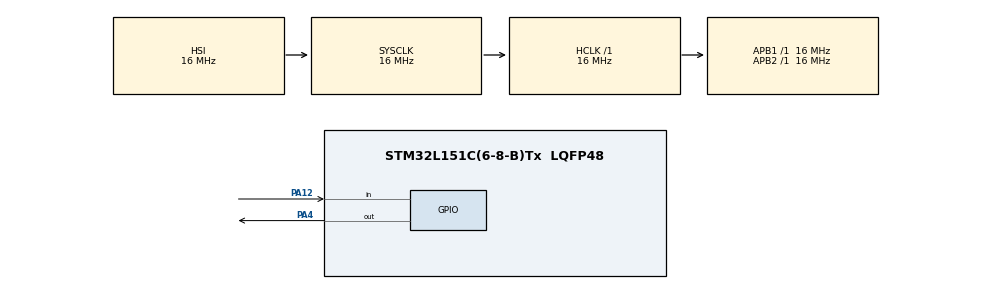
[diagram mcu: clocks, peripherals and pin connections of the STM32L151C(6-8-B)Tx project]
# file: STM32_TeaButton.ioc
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Mcu.Family=STM32L1
RCC.MSI_VALUE=2097000
RCC.SYSCLKSource=RCC_SYSCLKSOURCE_HSI
ProjectManager.StackSize=0x400
PA13.Signal=SYS_JTMS-SWDIO
PA12.Signal=GPIO_Input
ProjectManager.TargetToolchain=STM32CubeIDE
RCC.HCLKFreq_Value=16000000
RCC.APB2TimFreq_Value=16000000
RCC.LSE_VALUE=32768
RCC.AHBFreq_Value=16000000
RCC.HSE_VALUE=8000000
PB3.Mode=Trace_Asynchronous_SW
board=custom
RCC.VCOOutputFreq_Value=192000000
RCC.PLLMUL=RCC_PLL_MUL12
RCC.APB2Freq_Value=16000000
PA14.Mode=Trace_Asynchronous_SW
PA13.Mode=Trace_Asynchronous_SW
Mcu.Name=STM32L151C(6-8-B)Tx
RCC.48MHZClocksFreq_Value=96000000
PB3.Signal=SYS_JTDO-TRACESWO
PA4.Signal=GPIO_Output
RCC.SYSCLKFreq_VALUE=16000000
Mcu.Package=LQFP48
PA14.Signal=SYS_JTCK-SWCLK
ProjectManager.HeapSize=0x200
RCC.HSI_VALUE=16000000
NVIC.PriorityGroup=NVIC_PRIORITYGROUP_4
RCC.APB1TimFreq_Value=16000000
RCC.APB1Freq_Value=16000000

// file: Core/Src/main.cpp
/* USER CODE BEGIN Header */
/**
  ******************************************************************************
  * @file           : main.c
  * @brief          : Main program body
  ******************************************************************************
  * @attention
  *
  * <h2><center>&copy; Copyright (c) 2021 STMicroelectronics.
  * All rights reserved.</center></h2>
  *
  * This software component is licensed by ST under BSD 3-Clause license,
  * the "License"; You may not use this file except in compliance with the
  * License. You may obtain a copy of the License at:
  *                        opensource.org/licenses/BSD-3-Clause
  *
  ******************************************************************************
  */
/* USER CODE END Header */
#include "main.h"

/* USER CODE BEGIN Includes */
#include <stdio.h>
#include <TeaButton.h>
/* USER CODE END Includes */

void SystemClock_Config(void);
static void MX_GPIO_Init(void);

int main(void)
{

  /* MCU Configuration--------------------------------------------------------*/

  /* Reset of all peripherals, Initializes the Flash interface and the Systick. */
   HAL_Init();

  /* Configure the system clock */
  SystemClock_Config();

  /* Initialize all configured peripherals */
  MX_GPIO_Init();
  /* USER CODE BEGIN 2 */
  //HAL_GPIO_ReadPin(GPIOx, GPIO_Pin);

  TeaButton bt1 = TeaButton(GPIOA, GPIO_PIN_12);
  /* USER CODE END 2 */

  /* Infinite loop */
  while (1)
  {

    /* USER CODE BEGIN 3 */
	  if (bt1.isPress()){
		  HAL_GPIO_TogglePin(GPIOA, GPIO_PIN_4);
	  }
	  if (bt1.isRelease()){
		  HAL_GPIO_TogglePin(GPIOA, GPIO_PIN_4);
	  }
  }
  /* USER CODE END 3 */
}

void SystemClock_Config(void)
{
  RCC_OscInitTypeDef RCC_OscInitStruct = {0};
  RCC_ClkInitTypeDef RCC_ClkInitStruct = {0};

  /** Configure the main internal regulator output voltage
  */
  __HAL_PWR_VOLTAGESCALING_CONFIG(PWR_REGULATOR_VOLTAGE_SCALE1);
  /** Initializes the RCC Oscillators according to the specified parameters
  * in the RCC_OscInitTypeDef structure.
  */
  RCC_OscInitStruct.OscillatorType = RCC_OSCILLATORTYPE_HSI;
  RCC_OscInitStruct.HSIState = RCC_HSI_ON;
  RCC_OscInitStruct.HSICalibrationValue = RCC_HSICALIBRATION_DEFAULT;
  RCC_OscInitStruct.PLL.PLLState = RCC_PLL_NONE;
  if (HAL_RCC_OscConfig(&RCC_OscInitStruct) != HAL_OK)
  {
    Error_Handler();
  }
  /** Initializes the CPU, AHB and APB buses clocks
  */
  RCC_ClkInitStruct.ClockType = RCC_CLOCKTYPE_HCLK|RCC_CLOCKTYPE_SYSCLK
                              |RCC_CLOCKTYPE_PCLK1|RCC_CLOCKTYPE_PCLK2;
  RCC_ClkInitStruct.SYSCLKSource = RCC_SYSCLKSOURCE_HSI;
  RCC_ClkInitStruct.AHBCLKDivider = RCC_SYSCLK_DIV1;
  RCC_ClkInitStruct.APB1CLKDivider = RCC_HCLK_DIV1;
  RCC_ClkInitStruct.APB2CLKDivider = RCC_HCLK_DIV1;

  if (HAL_RCC_ClockConfig(&RCC_ClkInitStruct, FLASH_LATENCY_0) != HAL_OK)
  {
    Error_Handler();
  }
}

static void MX_GPIO_Init(void)
{
  GPIO_InitTypeDef GPIO_InitStruct = {0};

  /* GPIO Ports Clock Enable */
  __HAL_RCC_GPIOA_CLK_ENABLE();
  __HAL_RCC_GPIOB_CLK_ENABLE();

  /*Configure GPIO pin Output Level */
  HAL_GPIO_WritePin(GPIOA, GPIO_PIN_4, GPIO_PIN_RESET);

  /*Configure GPIO pin : PA4 */
  GPIO_InitStruct.Pin = GPIO_PIN_4;
  GPIO_InitStruct.Mode = GPIO_MODE_OUTPUT_PP;
  GPIO_InitStruct.Pull = GPIO_NOPULL;
  GPIO_InitStruct.Speed = GPIO_SPEED_FREQ_LOW;
  HAL_GPIO_Init(GPIOA, &GPIO_InitStruct);

  /*Configure GPIO pin : PA12 */
  GPIO_InitStruct.Pin = GPIO_PIN_12;
  GPIO_InitStruct.Mode = GPIO_MODE_INPUT;
  GPIO_InitStruct.Pull = GPIO_NOPULL;
  HAL_GPIO_Init(GPIOA, &GPIO_InitStruct);

}

void Error_Handler(void)
{
  __disable_irq();
  while (1)
  {
  }
}

/************************ (C) COPYRIGHT STMicroelectronics *****END OF FILE****/
